AUTOSAR XML (schema 4.0)
package /FeedbackProcessorComponent
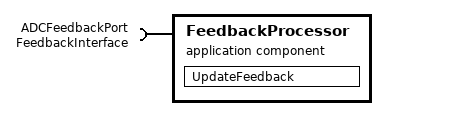
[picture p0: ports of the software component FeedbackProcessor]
  application software component type FeedbackProcessor
    require port ADCFeedbackPort: provided-interface=FeedbackInterface
    internal behavior FeedbackProcessorBehavior
      runnable UpdateFeedback
